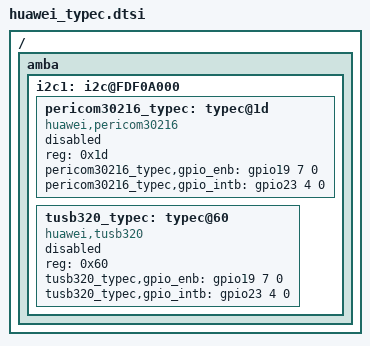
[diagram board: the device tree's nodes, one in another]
/*
 *
 * Copyright (C), 1988-1999, Huawei Tech. Co., Ltd.
 * Author: w00270068 <wangjing6@huawei.com>
 *
 * This program is free software; you can redistribute it and/or modify
 * it under the terms of the GNU General Public License version 2 as
 * publishhed by the Free Software Foundation.
 */

/{
	amba{
		i2c1: i2c@FDF0A000 {
			pericom30216_typec: typec@1d {
				compatible = "huawei,pericom30216";
				reg = <0x1d>;
				pericom30216_typec,gpio_enb = <&gpio19 7 0>;
				pericom30216_typec,gpio_intb = <&gpio23 4 0>;
				status = "disable";
			};

			tusb320_typec: typec@60 {
				compatible = "huawei,tusb320";
				reg = <0x60>;
				tusb320_typec,gpio_enb = <&gpio19 7 0>;
				tusb320_typec,gpio_intb = <&gpio23 4 0>;
				status = "disable";
			};
		};
	};
};
